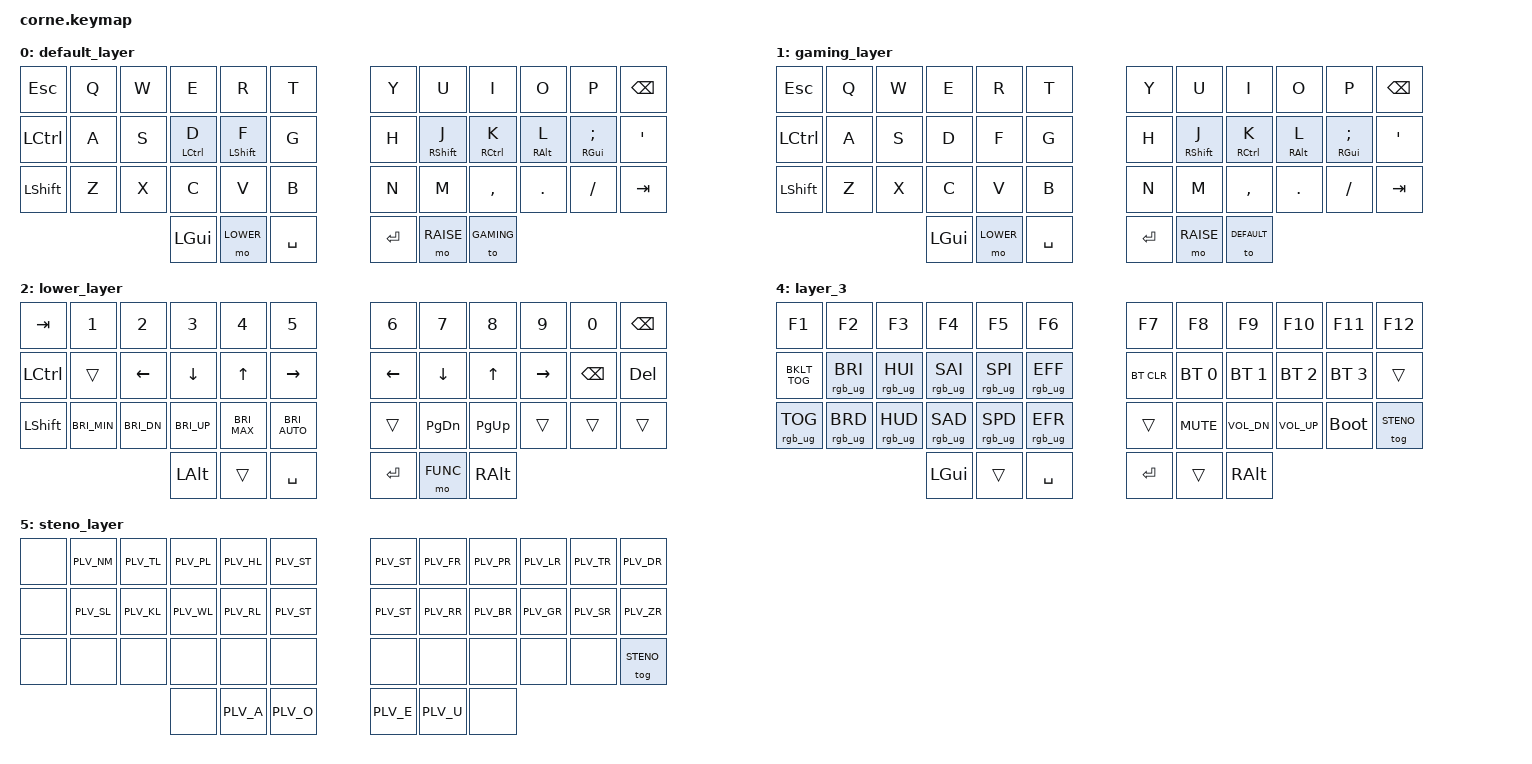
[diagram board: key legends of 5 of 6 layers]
/*
 * Copyright (c) 2020 The ZMK Contributors
 *
 * SPDX-License-Identifier: MIT
 */

#include <behaviors.dtsi>
#include <dt-bindings/zmk/bt.h>
#include <dt-bindings/zmk/keys.h>
#include <dt-bindings/zmk/rgb.h>
#include <dt-bindings/zmk/ext_power.h>

#define DEFAULT 0
#define GAMING  1
#define LOWER   2
#define RAISE   3
#define FUNC    4
#define STENO   5

/ {
    behaviors {
        hm: homerow_mods {
            compatible = "zmk,behavior-hold-tap";
            label = "HOMEROW_MODS";
            #binding-cells = <2>;
            tapping-term-ms = <200>;
            quick_tap_ms = <0>;
            flavor = "tap-preferred";
            bindings = <&kp>, <&kp>;

            quick-tap-ms = <180>;
            global-quick-tap;
        };

        ltq: ltq {
            compatible = "zmk,behavior-hold-tap";
            label = "LTQ";
            bindings = <&mo>, <&kp>;

            #binding-cells = <2>;
            tapping-term-ms = <600>;
            global-quick-tap;
            quick-tap-ms = <400>;
        };
    };

    combos {
        compatible = "zmk,combos";

        // left_bkt {
        //     bindings = <&kp LEFT_BRACKET>;
        //     key-positions = <4 3>;
        //     timeout-ms = <50>;
        //     layers = <0>;
        // };

        // right_bkt {
        //     bindings = <&kp RBKT>;
        //     key-positions = <7 8>;
        //     timeout-ms = <50>;
        //     layers = <0>;
        // };

        // left_par {
        //     bindings = <&kp LEFT_PARENTHESIS>;
        //     key-positions = <15 16>;
        //     timeout-ms = <50>;
        //     layers = <0>;
        // };

        // right_par {
        //     bindings = <&kp RIGHT_PARENTHESIS>;
        //     key-positions = <19 20>;
        //     timeout-ms = <50>;
        //     layers = <0>;
        // };

        // left_brace {
        //     bindings = <&kp LEFT_BRACE>;
        //     key-positions = <27 28>;
        //     timeout-ms = <50>;
        //     layers = <0>;
        // };

        // right_brace {
        //     bindings = <&kp RIGHT_BRACE>;
        //     key-positions = <32 31>;
        //     timeout-ms = <50>;
        //     layers = <0>;
        // };

        bac {
            bindings = <&kp BACKSLASH>;
            key-positions = <5 6>;
            layers = <DEFAULT>;
        };

        pipe {
            bindings = <&kp PIPE>;
            key-positions = <17 18>;
            layers = <DEFAULT>;
        };

        backspace {
            bindings = <&kp BSPC>;
            key-positions = <16 19>;  
            layers = <DEFAULT>;
        };
    };

    keymap {
        compatible = "zmk,keymap";

        default_layer {
            bindings = <
&kp ESC    &kp Q           &kp W           &kp E        &kp R             &kp T        &kp Y  &kp U             &kp I          &kp O            &kp P               &kp BSPC
&kp LCTRL  &kp A  &kp S  &hm LCTRL D  &hm LEFT_SHIFT F  &kp G        &kp H  &hm RSHIFT J      &hm RCTRL K    &hm RIGHT_ALT L  &hm RGUI SEMICOLON  &kp SQT
&kp LSHFT  &kp Z           &kp X           &kp C        &kp V             &kp B        &kp N  &kp M             &kp COMMA      &kp DOT          &kp FSLH            &kp TAB
                                           &kp LGUI      &mo LOWER       &kp SPACE  &kp RET  &mo RAISE  &to GAMING
            >;
        };

        gaming_layer {
            bindings = <
&kp ESC    &kp Q           &kp W           &kp E        &kp R             &kp T        &kp Y  &kp U             &kp I          &kp O            &kp P               &kp BSPC
&kp LCTRL  &kp A           &kp S           &kp D        &kp F             &kp G        &kp H  &hm RSHIFT J      &hm RCTRL K    &hm RIGHT_ALT L  &hm RGUI SEMICOLON  &kp SQT
&kp LSHFT  &kp Z           &kp X           &kp C        &kp V             &kp B        &kp N  &kp M             &kp COMMA      &kp DOT          &kp FSLH            &kp TAB
                                           &kp LGUI      &mo LOWER       &kp SPACE  &kp RET  &mo RAISE  &to DEFAULT
            >;
        };

        lower_layer {
            bindings = <
&kp TAB   &kp N1        &kp N2        &kp N3       &kp N4        &kp N5           &kp N6   &kp N7    &kp N8    &kp N9    &kp N0   &kp BSPC
&kp LCTRL &trans        &kp LEFT      &kp DOWN     &kp UP        &kp RIGHT        &kp LEFT &kp DOWN  &kp UP    &kp RIGHT &kp BSPC &kp DEL
&kp LSHFT &kp C_BRI_MIN &kp C_BRI_DN  &kp C_BRI_UP &kp C_BRI_MAX &kp C_BRI_AUTO   &trans   &kp PG_DN &kp PG_UP &trans    &trans   &trans
                                        &kp LALT     &trans        &kp SPACE        &kp RET  &mo FUNC     &kp RALT
            >;
        };

        raise_layer {
            bindings = <
&kp  TAB  &kp EXCL &kp AT &kp HASH &kp DLLR &kp PRCNT   &kp CARET &kp AMPS  &kp ASTRK &kp LPAR &kp RPAR &kp BSPC
&kp LCTRL &trans   &trans &trans   &trans   &trans      &kp MINUS &kp EQUAL &kp LBKT  &kp RBKT &kp BSLH &kp GRAVE
&kp LSHFT &trans   &trans &trans   &trans   &trans      &kp UNDER &kp PLUS  &kp LBRC  &kp RBRC &kp PIPE &kp TILDE
                            &kp LGUI &mo FUNC   &kp SPACE   &kp RET   &trans    &kp RALT         &trans    &trans    &trans
            >;
        };

        layer_3 {
            bindings = <
&kp  F1         &kp F2          &kp F3          &kp F4          &kp F5           &kp F6             &kp F7      &kp F8       &kp F9       &kp F10      &kp F11      &kp F12
&kp C_BKLT_TOG  &rgb_ug RGB_BRI &rgb_ug RGB_HUI &rgb_ug RGB_SAI &rgb_ug RGB_SPI  &rgb_ug RGB_EFF    &bt BT_CLR  &bt BT_SEL 0 &bt BT_SEL 1 &bt BT_SEL 2 &bt BT_SEL 3 &trans
&rgb_ug RGB_TOG &rgb_ug RGB_BRD &rgb_ug RGB_HUD &rgb_ug RGB_SAD &rgb_ug RGB_SPD  &rgb_ug RGB_EFR    &trans      &kp C_MUTE   &kp C_VOL_DN &kp C_VOL_UP &bootloader  &tog STENO
                                                &kp LGUI        &trans           &kp SPACE          &kp RET     &trans       &kp RALT
            >;
        };

        steno_layer {
            // display-name = "Steno";
            bindings = <
&none &kp PLV_NM &kp PLV_TL &kp PLV_PL &kp PLV_HL &kp PLV_ST   &kp PLV_ST &kp PLV_FR &kp PLV_PR &kp PLV_LR &kp PLV_TR &kp PLV_DR
&none &kp PLV_SL &kp PLV_KL &kp PLV_WL &kp PLV_RL &kp PLV_ST   &kp PLV_ST &kp PLV_RR &kp PLV_BR &kp PLV_GR &kp PLV_SR &kp PLV_ZR
&none &none &none &none &none &none   &none &none &none &none &none &tog STENO
                &none &kp PLV_A &kp PLV_O &kp PLV_E &kp PLV_U &none
                >;
        };

        extra1 {
            status = "reserved";
        };
        extra2 {
            status = "reserved";
        };
        extra3 {
            status = "reserved";
        };
        extra4 {
            status = "reserved";
        };

    };
};
